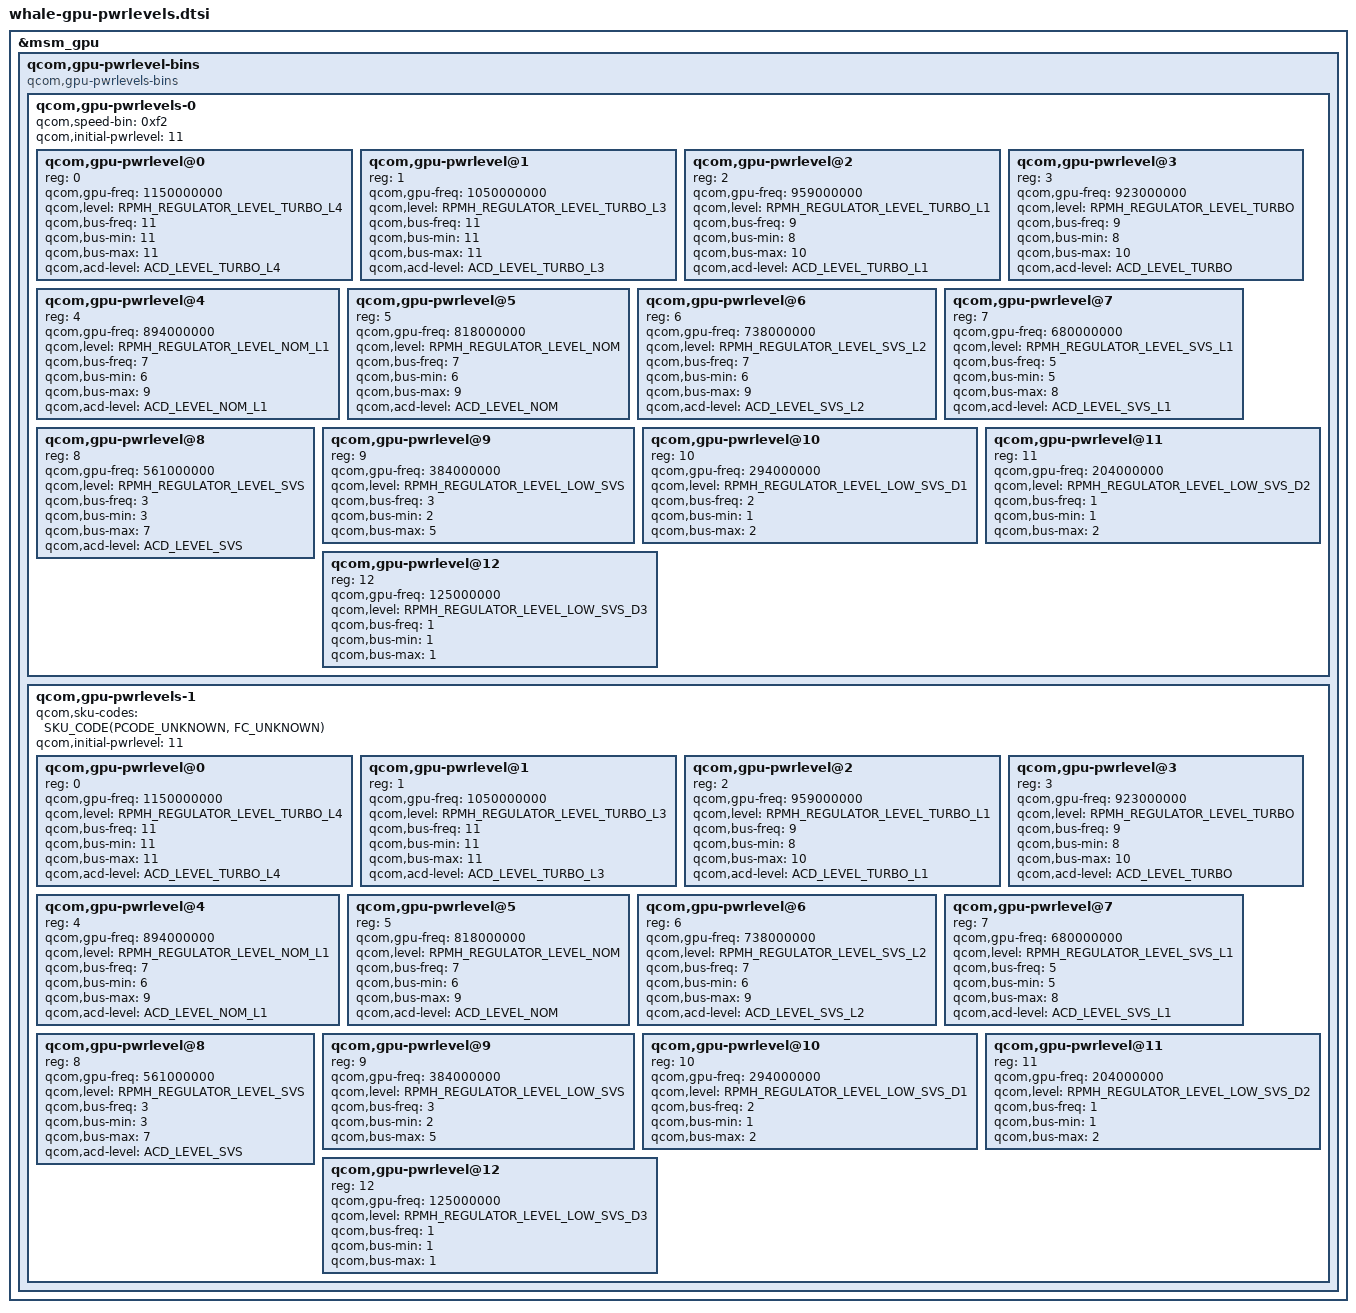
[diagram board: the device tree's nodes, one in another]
// SPDX-License-Identifier: BSD-3-Clause
/*
 * Copyright (c) Qualcomm Technologies, Inc. and/or its subsidiaries.
 */

#define ACD_LEVEL_TURBO_L4       0x88285FFD
#define ACD_LEVEL_TURBO_L3       0x882A5FFD
#define ACD_LEVEL_TURBO_L1       0x882B5FFD
#define ACD_LEVEL_TURBO          0xA82B5FFD
#define ACD_LEVEL_NOM_L1         0xA82B5FFD
#define ACD_LEVEL_NOM            0xA82C5FFD
#define ACD_LEVEL_SVS_L2         0x882F5FFD
#define ACD_LEVEL_SVS_L1         0XC02A5FFD
#define ACD_LEVEL_SVS            0XC02C5FFD

&msm_gpu {
	/* Power Levels */
	qcom,gpu-pwrlevel-bins {
		#address-cells = <1>;
		#size-cells = <0>;

		compatible = "qcom,gpu-pwrlevels-bins";

		/* Keep the pwrlevel bins sorted on the highest qcom,gpu-freq */
		qcom,gpu-pwrlevels-0 {
			#address-cells = <1>;
			#size-cells = <0>;

			qcom,speed-bin = <0xf2>;
			qcom,initial-pwrlevel = <11>;

			/* TURBO_L4 */
			qcom,gpu-pwrlevel@0 {
				reg = <0>;
				qcom,gpu-freq = <1150000000>;
				qcom,level = <RPMH_REGULATOR_LEVEL_TURBO_L4>;

				qcom,bus-freq = <11>;
				qcom,bus-min = <11>;
				qcom,bus-max = <11>;

				qcom,acd-level = <ACD_LEVEL_TURBO_L4>;
			};

			/* TURBO_L3 */
			qcom,gpu-pwrlevel@1 {
				reg = <1>;
				qcom,gpu-freq = <1050000000>;
				qcom,level = <RPMH_REGULATOR_LEVEL_TURBO_L3>;

				qcom,bus-freq = <11>;
				qcom,bus-min = <11>;
				qcom,bus-max = <11>;

				qcom,acd-level = <ACD_LEVEL_TURBO_L3>;
			};

			/* TURBO_L1 */
			qcom,gpu-pwrlevel@2 {
				reg = <2>;
				qcom,gpu-freq = <959000000>;
				qcom,level = <RPMH_REGULATOR_LEVEL_TURBO_L1>;

				qcom,bus-freq = <9>;
				qcom,bus-min = <8>;
				qcom,bus-max = <10>;

				qcom,acd-level = <ACD_LEVEL_TURBO_L1>;
			};

			/* TURBO */
			qcom,gpu-pwrlevel@3 {
				reg = <3>;
				qcom,gpu-freq = <923000000>;
				qcom,level = <RPMH_REGULATOR_LEVEL_TURBO>;

				qcom,bus-freq = <9>;
				qcom,bus-min = <8>;
				qcom,bus-max = <10>;

				qcom,acd-level = <ACD_LEVEL_TURBO>;
			};

			/* NOM_L1 */
			qcom,gpu-pwrlevel@4 {
				reg = <4>;
				qcom,gpu-freq = <894000000>;
				qcom,level = <RPMH_REGULATOR_LEVEL_NOM_L1>;

				qcom,bus-freq = <7>;
				qcom,bus-min = <6>;
				qcom,bus-max = <9>;

				qcom,acd-level = <ACD_LEVEL_NOM_L1>;
			};

			/* NOM */
			qcom,gpu-pwrlevel@5 {
				reg = <5>;
				qcom,gpu-freq = <818000000>;
				qcom,level = <RPMH_REGULATOR_LEVEL_NOM>;

				qcom,bus-freq = <7>;
				qcom,bus-min = <6>;
				qcom,bus-max = <9>;

				qcom,acd-level = <ACD_LEVEL_NOM>;
			};

			/* SVS_L2 */
			qcom,gpu-pwrlevel@6 {
				reg = <6>;
				qcom,gpu-freq = <738000000>;
				qcom,level = <RPMH_REGULATOR_LEVEL_SVS_L2>;

				qcom,bus-freq = <7>;
				qcom,bus-min = <6>;
				qcom,bus-max = <9>;

				qcom,acd-level = <ACD_LEVEL_SVS_L2>;
			};

			/* SVS_L1 */
			qcom,gpu-pwrlevel@7 {
				reg = <7>;
				qcom,gpu-freq = <680000000>;
				qcom,level = <RPMH_REGULATOR_LEVEL_SVS_L1>;

				qcom,bus-freq = <5>;
				qcom,bus-min = <5>;
				qcom,bus-max = <8>;

				qcom,acd-level = <ACD_LEVEL_SVS_L1>;
			};

			/* SVS */
			qcom,gpu-pwrlevel@8 {
				reg = <8>;
				qcom,gpu-freq = <561000000>;
				qcom,level = <RPMH_REGULATOR_LEVEL_SVS>;

				qcom,bus-freq = <3>;
				qcom,bus-min = <3>;
				qcom,bus-max = <7>;

				qcom,acd-level = <ACD_LEVEL_SVS>;
			};

			/* LOW_SVS */
			qcom,gpu-pwrlevel@9 {
				reg = <9>;
				qcom,gpu-freq = <384000000>;
				qcom,level = <RPMH_REGULATOR_LEVEL_LOW_SVS>;

				qcom,bus-freq = <3>;
				qcom,bus-min = <2>;
				qcom,bus-max = <5>;
			};

			/* LOW_SVS_D1 */
			qcom,gpu-pwrlevel@10 {
				reg = <10>;
				qcom,gpu-freq = <294000000>;
				qcom,level = <RPMH_REGULATOR_LEVEL_LOW_SVS_D1>;

				qcom,bus-freq = <2>;
				qcom,bus-min = <1>;
				qcom,bus-max = <2>;
			};

			/* LOW_SVS_D2 */
			qcom,gpu-pwrlevel@11 {
				reg = <11>;
				qcom,gpu-freq = <204000000>;
				qcom,level = <RPMH_REGULATOR_LEVEL_LOW_SVS_D2>;

				qcom,bus-freq = <1>;
				qcom,bus-min = <1>;
				qcom,bus-max = <2>;
			};

			/* LOW_SVS_D3 */
			qcom,gpu-pwrlevel@12 {
				reg = <12>;
				qcom,gpu-freq = <125000000>;
				qcom,level = <RPMH_REGULATOR_LEVEL_LOW_SVS_D3>;

				qcom,bus-freq = <1>;
				qcom,bus-min = <1>;
				qcom,bus-max = <1>;
			};
		};

		qcom,gpu-pwrlevels-1 {
			#address-cells = <1>;
			#size-cells = <0>;

			qcom,sku-codes = <SKU_CODE(PCODE_UNKNOWN, FC_UNKNOWN)>;
			qcom,initial-pwrlevel = <11>;

			/* TURBO_L4 */
			qcom,gpu-pwrlevel@0 {
				reg = <0>;
				qcom,gpu-freq = <1150000000>;
				qcom,level = <RPMH_REGULATOR_LEVEL_TURBO_L4>;

				qcom,bus-freq = <11>;
				qcom,bus-min = <11>;
				qcom,bus-max = <11>;

				qcom,acd-level = <ACD_LEVEL_TURBO_L4>;
			};

			/* TURBO_L3 */
			qcom,gpu-pwrlevel@1 {
				reg = <1>;
				qcom,gpu-freq = <1050000000>;
				qcom,level = <RPMH_REGULATOR_LEVEL_TURBO_L3>;

				qcom,bus-freq = <11>;
				qcom,bus-min = <11>;
				qcom,bus-max = <11>;

				qcom,acd-level = <ACD_LEVEL_TURBO_L3>;
			};

			/* TURBO_L1 */
			qcom,gpu-pwrlevel@2 {
				reg = <2>;
				qcom,gpu-freq = <959000000>;
				qcom,level = <RPMH_REGULATOR_LEVEL_TURBO_L1>;

				qcom,bus-freq = <9>;
				qcom,bus-min = <8>;
				qcom,bus-max = <10>;

				qcom,acd-level = <ACD_LEVEL_TURBO_L1>;
			};

			/* TURBO */
			qcom,gpu-pwrlevel@3 {
				reg = <3>;
				qcom,gpu-freq = <923000000>;
				qcom,level = <RPMH_REGULATOR_LEVEL_TURBO>;

				qcom,bus-freq = <9>;
				qcom,bus-min = <8>;
				qcom,bus-max = <10>;

				qcom,acd-level = <ACD_LEVEL_TURBO>;
			};

			/* NOM_L1 */
			qcom,gpu-pwrlevel@4 {
				reg = <4>;
				qcom,gpu-freq = <894000000>;
				qcom,level = <RPMH_REGULATOR_LEVEL_NOM_L1>;

				qcom,bus-freq = <7>;
				qcom,bus-min = <6>;
				qcom,bus-max = <9>;

				qcom,acd-level = <ACD_LEVEL_NOM_L1>;
			};

			/* NOM */
			qcom,gpu-pwrlevel@5 {
				reg = <5>;
				qcom,gpu-freq = <818000000>;
				qcom,level = <RPMH_REGULATOR_LEVEL_NOM>;

				qcom,bus-freq = <7>;
				qcom,bus-min = <6>;
				qcom,bus-max = <9>;

				qcom,acd-level = <ACD_LEVEL_NOM>;
			};

			/* SVS_L2 */
			qcom,gpu-pwrlevel@6 {
				reg = <6>;
				qcom,gpu-freq = <738000000>;
				qcom,level = <RPMH_REGULATOR_LEVEL_SVS_L2>;

				qcom,bus-freq = <7>;
				qcom,bus-min = <6>;
				qcom,bus-max = <9>;

				qcom,acd-level = <ACD_LEVEL_SVS_L2>;
			};

			/* SVS_L1 */
			qcom,gpu-pwrlevel@7 {
				reg = <7>;
				qcom,gpu-freq = <680000000>;
				qcom,level = <RPMH_REGULATOR_LEVEL_SVS_L1>;

				qcom,bus-freq = <5>;
				qcom,bus-min = <5>;
				qcom,bus-max = <8>;

				qcom,acd-level = <ACD_LEVEL_SVS_L1>;
			};

			/* SVS */
			qcom,gpu-pwrlevel@8 {
				reg = <8>;
				qcom,gpu-freq = <561000000>;
				qcom,level = <RPMH_REGULATOR_LEVEL_SVS>;

				qcom,bus-freq = <3>;
				qcom,bus-min = <3>;
				qcom,bus-max = <7>;

				qcom,acd-level = <ACD_LEVEL_SVS>;
			};

			/* LOW_SVS */
			qcom,gpu-pwrlevel@9 {
				reg = <9>;
				qcom,gpu-freq = <384000000>;
				qcom,level = <RPMH_REGULATOR_LEVEL_LOW_SVS>;

				qcom,bus-freq = <3>;
				qcom,bus-min = <2>;
				qcom,bus-max = <5>;
			};

			/* LOW_SVS_D1 */
			qcom,gpu-pwrlevel@10 {
				reg = <10>;
				qcom,gpu-freq = <294000000>;
				qcom,level = <RPMH_REGULATOR_LEVEL_LOW_SVS_D1>;

				qcom,bus-freq = <2>;
				qcom,bus-min = <1>;
				qcom,bus-max = <2>;
			};

			/* LOW_SVS_D2 */
			qcom,gpu-pwrlevel@11 {
				reg = <11>;
				qcom,gpu-freq = <204000000>;
				qcom,level = <RPMH_REGULATOR_LEVEL_LOW_SVS_D2>;

				qcom,bus-freq = <1>;
				qcom,bus-min = <1>;
				qcom,bus-max = <2>;
			};

			/* LOW_SVS_D3 */
			qcom,gpu-pwrlevel@12 {
				reg = <12>;
				qcom,gpu-freq = <125000000>;
				qcom,level = <RPMH_REGULATOR_LEVEL_LOW_SVS_D3>;

				qcom,bus-freq = <1>;
				qcom,bus-min = <1>;
				qcom,bus-max = <1>;
			};
		};
	};
};
